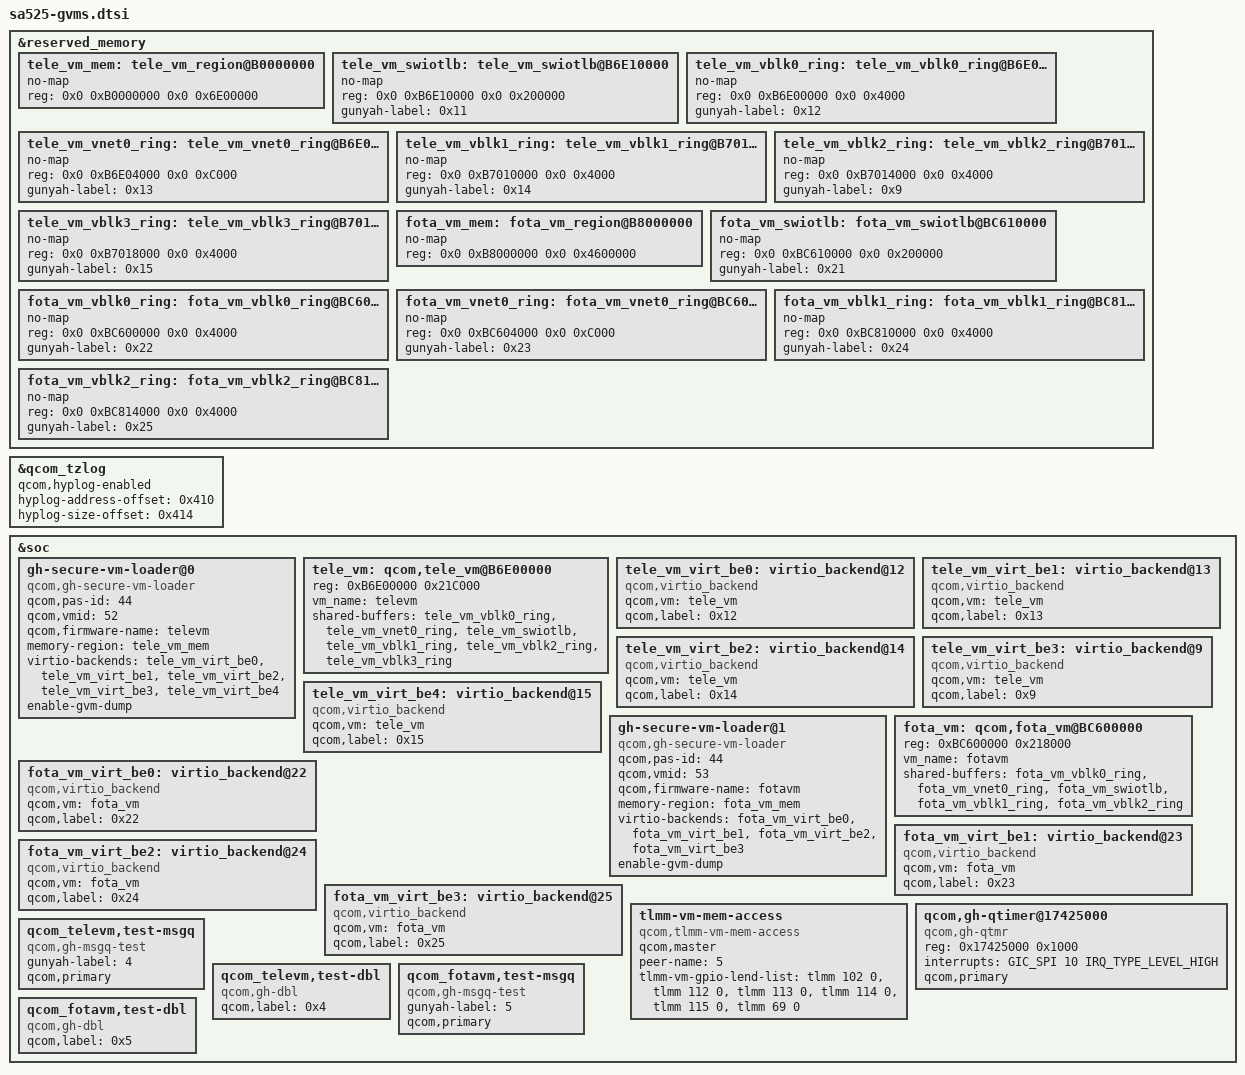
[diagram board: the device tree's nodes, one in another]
&reserved_memory {
	/* Size of TeleVM is 90MB */
	tele_vm_mem: tele_vm_region@B0000000 {
		no-map;
		reg = <0x0 0xB0000000 0x0 0x6E00000>;
	};

	tele_vm_swiotlb: tele_vm_swiotlb@B6E10000 {
		no-map;
		reg = <0x0 0xB6E10000 0x0 0x200000>;
		gunyah-label = <0x11>;
	};

	tele_vm_vblk0_ring: tele_vm_vblk0_ring@B6E00000 {
		no-map;
		reg = <0x0 0xB6E00000 0x0 0x4000>;
		gunyah-label = <0x12>;			//for sdcard
	};


	tele_vm_vnet0_ring: tele_vm_vnet0_ring@B6E04000 {
		no-map;
		reg = <0x0 0xB6E04000 0x0 0xC000>;
		gunyah-label = <0x13>;
	};

	tele_vm_vblk1_ring: tele_vm_vblk1_ring@B7010000 {
		no-map;
		reg = <0x0 0xB7010000 0x0 0x4000>;
		gunyah-label = <0x14>;			//for systemrw.img
	};

	tele_vm_vblk2_ring: tele_vm_vblk2_ring@B7014000 {
		no-map;
		reg = <0x0 0xB7014000 0x0 0x4000>;
		gunyah-label = <0x9>;			//for vhost scmi
	};

	tele_vm_vblk3_ring: tele_vm_vblk3_ring@B7018000 {
		no-map;
		reg = <0x0 0xB7018000 0x0 0x4000>;
		gunyah-label = <0x15>;			//for system.img
	};

	/* Size of FotaVM is 60MB */
	fota_vm_mem: fota_vm_region@B8000000 {
		no-map;
		reg = <0x0 0xB8000000 0x0 0x4600000>;
	};

	fota_vm_swiotlb: fota_vm_swiotlb@BC610000 {
		no-map;
		reg = <0x0 0xBC610000 0x0 0x200000>;
		gunyah-label = <0x21>;
	};

	fota_vm_vblk0_ring: fota_vm_vblk0_ring@BC600000 {
		no-map;
		reg = <0x0 0xBC600000 0x0 0x4000>;
		gunyah-label = <0x22>;			//for sdcard.img
	};

	fota_vm_vnet0_ring: fota_vm_vnet0_ring@BC604000 {
		no-map;
		reg = <0x0 0xBC604000 0x0 0xC000>;
		gunyah-label = <0x23>;
	};

	fota_vm_vblk1_ring: fota_vm_vblk1_ring@BC810000 {
		no-map;
		reg = <0x0 0xBC810000 0x0 0x4000>;
		gunyah-label = <0x24>;			//for systemrw.img
	};

	fota_vm_vblk2_ring: fota_vm_vblk2_ring@BC814000 {
		no-map;
		reg = <0x0 0xBC814000 0x0 0x4000>;
		gunyah-label = <0x25>;			//for system.img
	};
};

&qcom_tzlog {
	qcom,hyplog-enabled;
	hyplog-address-offset = <0x410>;
	hyplog-size-offset = <0x414>;
};

&soc {

	gh-secure-vm-loader@0 {
		compatible = "qcom,gh-secure-vm-loader";
		qcom,pas-id = <44>;
		qcom,vmid = <52>;
		qcom,firmware-name = "televm";
		memory-region = <&tele_vm_mem>;
		virtio-backends = <&tele_vm_virt_be0 &tele_vm_virt_be1 &tele_vm_virt_be2 &tele_vm_virt_be3 &tele_vm_virt_be4>;
		enable-gvm-dump;
	};

	tele_vm: qcom,tele_vm@B6E00000 {
		reg = <0xB6E00000 0x21C000>;
		vm_name = "televm";
		shared-buffers = <&tele_vm_vblk0_ring &tele_vm_vnet0_ring &tele_vm_swiotlb &tele_vm_vblk1_ring &tele_vm_vblk2_ring &tele_vm_vblk3_ring>;
	};

	tele_vm_virt_be0:virtio_backend@12 {
		compatible = "qcom,virtio_backend";
		qcom,vm = <&tele_vm>;
		qcom,label = <0x12>;
	};

	tele_vm_virt_be1:virtio_backend@13 {
		compatible = "qcom,virtio_backend";
		qcom,vm = <&tele_vm>;
		qcom,label = <0x13>;
	};

	tele_vm_virt_be2:virtio_backend@14 {
		compatible = "qcom,virtio_backend";
		qcom,vm = <&tele_vm>;
		qcom,label = <0x14>;
	};

	tele_vm_virt_be3:virtio_backend@9 {
		compatible = "qcom,virtio_backend";
		qcom,vm = <&tele_vm>;
		qcom,label = <0x9>;
	};

	tele_vm_virt_be4:virtio_backend@15 {
		compatible = "qcom,virtio_backend";
		qcom,vm = <&tele_vm>;
		qcom,label = <0x15>;
	};

	gh-secure-vm-loader@1 {
		compatible = "qcom,gh-secure-vm-loader";
		qcom,pas-id = <44>;
		qcom,vmid = <53>;
		qcom,firmware-name = "fotavm";
		memory-region = <&fota_vm_mem>;
		virtio-backends = <&fota_vm_virt_be0 &fota_vm_virt_be1 &fota_vm_virt_be2 &fota_vm_virt_be3>;
		enable-gvm-dump;
	};

	fota_vm: qcom,fota_vm@BC600000 {
		reg = <0xBC600000 0x218000>;
		vm_name = "fotavm";
		shared-buffers = <&fota_vm_vblk0_ring &fota_vm_vnet0_ring &fota_vm_swiotlb &fota_vm_vblk1_ring &fota_vm_vblk2_ring>;
	};

	fota_vm_virt_be0:virtio_backend@22 {
		compatible = "qcom,virtio_backend";
		qcom,vm = <&fota_vm>;
		qcom,label = <0x22>;
	};

	fota_vm_virt_be1:virtio_backend@23 {
		compatible = "qcom,virtio_backend";
		qcom,vm = <&fota_vm>;
		qcom,label = <0x23>;
	};

	fota_vm_virt_be2:virtio_backend@24 {
		compatible = "qcom,virtio_backend";
		qcom,vm = <&fota_vm>;
		qcom,label = <0x24>;
	};

	fota_vm_virt_be3:virtio_backend@25 {
		compatible = "qcom,virtio_backend";
		qcom,vm = <&fota_vm>;
		qcom,label = <0x25>;
	};

	tlmm-vm-mem-access {
		compatible = "qcom,tlmm-vm-mem-access";
		qcom,master;
		peer-name = <5>; /* 5 => Televm */
		tlmm-vm-gpio-lend-list = <&tlmm 102 0 &tlmm 112 0 &tlmm 113 0 &tlmm 114 0 &tlmm 115 0 &tlmm 69 0>;
	};

	qcom,gh-qtimer@17425000 {
		compatible = "qcom,gh-qtmr";
		reg = <0x17425000 0x1000>;
		reg-names = "qtmr-base";
		interrupts = <GIC_SPI 10 IRQ_TYPE_LEVEL_HIGH>;
		interrupt-names = "qcom,qtmr-intr";
		qcom,primary;
	};

	qcom_televm,test-msgq {
		compatible = "qcom,gh-msgq-test";
		gunyah-label = <4>;
		qcom,primary;
	};

	qcom_televm,test-dbl {
		compatible = "qcom,gh-dbl";
		qcom,label = <0x4>;
	};

	qcom_fotavm,test-msgq {
		compatible = "qcom,gh-msgq-test";
		gunyah-label = <5>;
		qcom,primary;
	};

	qcom_fotavm,test-dbl {
		compatible = "qcom,gh-dbl";
		qcom,label = <0x5>;
	};
};
